# G32R430xx register map
Vendor: Geehy Semiconductor Co., Ltd.; Series: G32R4; File version: 1.0
G32R430xx SVD G32R430xx ARM 32-bit Cortex-M52 Microcontroller based device
CPU: CM52 r0p1, little endian, MPU, no FPU, DSP, VTOR, 4 interrupt priority bits
Registers are 32-bit, read-write, reset 0x0 unless marked. A register's access mark holds for its fields unless they carry their own. Offsets are from the block's base; lines under a group give offsets from that group; [hi:lo] are bit positions; {n}, {i} and the like mark numbered series; 'fields as' and 'values as' point back to an identical list; <NAME> marks a mode.

## Memory map
0x40000000 TMR1 size 0x400 — Advanced timer
0x40000400 TMR2 size 0x400 — General purpose timer
0x40000800 TMR3 size 0x400 — General purpose timer
0x40000C00 TMR4 size 0x400 — General purpose timer
0x40001000 SPI1 size 0x400 — Serial peripheral interface
0x40001400 USART1 size 0x400 — Universal synchronous asynchronous receiver transmitter
0x40001800 USART2 size 0x400
0x40001C00 I2C1 size 0x400 — Inter integrated circuit 1
0x40002000 WWDT size 0x400 — Window watchdog
0x40002400 IWDT size 0x400 — Independent watchdog
0x40002800 EINT size 0x400 — External Interrupt
0x40002C00 DAC1 size 0x400 — Digital to analog converter
0x40003000 DAC2 size 0x400 — Digital to analog converter
0x40003400 COMP size 0x400 — Comparator
0x40003800 PMU size 0x30 — Power manage unit
0x40003830 BAKPR size 0x100 — Back up registers
0x40003A00 RTC size 0x100 — Real time clock
0x40003B00 LPTMR size 0x100 — Low-power timer
0x40003C00 TS size 0x100 — Temperature sensor
0x40005800 DBGMCU size 0x400 — Debug support
0x40020000 DMA size 0x400 — DMA controller
0x40020400 RCM size 0x400 — Reset and clock manager.
0x40020800 FMC size 0x400 — Flash memory controller
0x40020C00 ADC1 size 0x400 — Analog to digital converter(16 bit)
0x40021000 ADC2 size 0x400 — Analog to digital converter(16 bit)
0x40021400 ADC3 size 0x400 — Analog to digital converter(12 bit)
0x40021800 GPIO size 0x400 — General purpose I/O
0xE000E000 NVIC size 0x1001 — Nested Vectored Interrupt Controller

## Interrupts
0 WWDT — Window Watchdog interrupt
1 FLASH (FMC) — Flash global interrupt
2 RCU (RCM) — RCU global interrupt
3 RTC — RTC global interrupt
{n+4} DMA1_Stream{n} (DMA) (n=0..7) — DMA1 Stream {n} global interrupt
12 ADC1 — ADC1 global interrupt
13 ADC2 — ADC2 global interrupt
14 ADC3 — ADC3 global interrupt
15 TMR1 — TMR1 global interrupt
16 TMR2 — TMR2 global interrupt
17 TMR3 — TMR3 global interrupt
18 TMR4 — TMR4 global interrupt
19 SPI1 — SPI1 global interrupt
20 USART1 — USART1 global interrupt
21 USART2 — USART2 global interrupt
22 I2C1 — I2C1 golbal interrupt
23 LPTMR — LPTMR global interrupt
24 EINT0 (EINT) — EINT Line0 interrupt
25 EINT1 (EINT) — EINT Line1 interrupt
26 EINT2 (EINT) — EINT Line2 interrupt
27 EINT3 (EINT) — EINT Line3 interrupt
28 EINT4 (EINT) — EINT Line4 interrupt
29 EINT5_9 (EINT) — EINT Line[9:5] interrupts
30 EINT10_15 (EINT) — EINT Line[15:10] interrupts
31 PVD (PMU) — PVD through EINT16 Line detection Interrupt
32 RTC_ALARM (RTC) — RTC_ALARM through EINT17 Line detection Interrupt
33 EVS (PMU) — Main Power Wake-up Interrupt
34 COMP1 (COMP) — COMP0 global interrupt
35 COMP2 (COMP) — COMP1 global interrupt
36 COMP3 (COMP) — COMP2 global interrupt
37 COMP4 (COMP) — COMP3 global interrupt
38 TS — TS Temperature Sensor Interrupt

## FMC — Flash memory controller
Base 0x40020800
0x00 KEY wo
  [31:0] FKEY — FLASH KEY
0x04 OPTKEY wo — option byte key register
  [31:0] OPTKEY — Option byte key
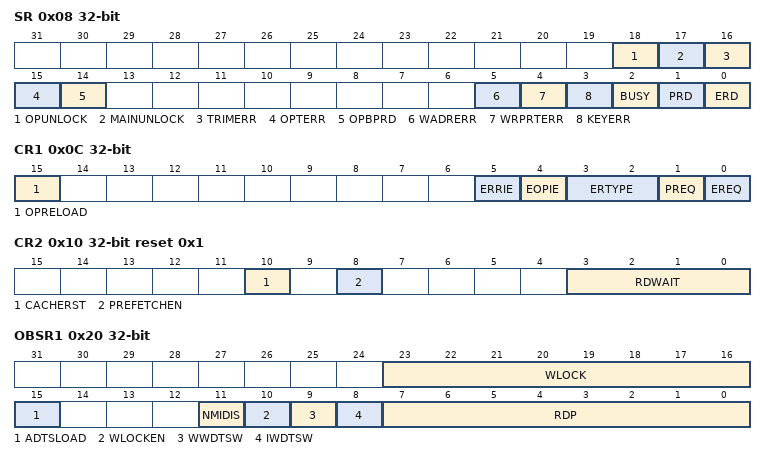
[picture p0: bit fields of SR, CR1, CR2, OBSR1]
0x08 SR access per field — status register
  [18] OPUNLOCK rw — Option byte area lock flag
  [17] MAINUNLOCK rw — Main program area lock flag.
  [16] TRIMERR ro — Trim check error
  [15] OPTERR ro — option_byte does not pass the positive and negative code verification.
  [14] OPBPRD rw — Option byte programming completion flag
  [5] WADRERR rw — Incorrect address written.
  [4] WRPRTERR rw — Write protection error flag.
  [3] KEYERR rw — Flash KEY error
  [2] BUSY ro
  [1] PRD rw — Programming completion
  [0] ERD rw — Erase completion
0x0C CR1 access per field — Control register 1
  [15] OPRELOAD wo — Options Byte Forced Update
  [5] ERRIE rw — Error Interrupt Occurred
  [4] EOPIE rw — Programming or clearing end of interrupt enable.
  [3:2] ERTYPE rw — Flash erase type configuration
  [1] PREQ rw — Program Request
  [0] EREQ rw — Erase Request
0x10 CR2 reset 0x1 — Control register 2
  [10] CACHERST — cache - reset operation
  [8] PREFETCHEN — Prefetch Enable
  [3:0] RDWAIT — Reading Flash-wait time setting
0x18 TMCR reset 0xFF
  [7:0] UNIT — Flash/EEPROM 1us Unit Counter
0x20 OBSR1 ro — Option Byte Status Register 1
  [23:16] WLOCK — Write protect sector
  [15] ADTSLOAD — ADC TRIM Value Load Configuration
  [11] NMIDIS — NMI Pin Enable Configuration
  [10] WLOCKEN — Write protection enabled.
  [9] WWDTSW — Hardware WWDT switch
  [8] IWDTSW — Hardware IWDT switch
  [7:0] RDP — Read protection switch
0x24 OBSR2 ro — Option Byte Status Register 2
  [15:0] BOOTADDR
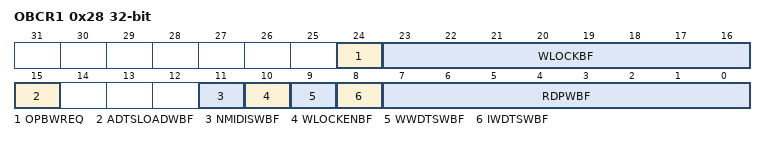
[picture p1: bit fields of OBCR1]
0x28 OBCR1 — Option Byte Control Register 1
  [24] OPBWREQ — option_byte write request
  [23:16] WLOCKBF — Write protect sector
  [15] ADTSLOADWBF — ADC TRIM Value Load Configuration
  [11] NMIDISWBF — NMI Pin Enable Configuration
  [10] WLOCKENBF — Write protection enabled.
  [9] WWDTSWBF — Hardware WWDT switch
  [8] IWDTSWBF — Hardware IWDT switch
  [7:0] RDPWBF — Read protection switch
0x2C OBCR2 — Option Byte Control Register 2
  [15:0] BOOTADDRBF — BOOTADDRWBF
